# PIC32MK1024MCF064 device description
Architecture: MIPS; Family: PIC32MK; Series: PIC32MK
Registers are 32-bit, read-write, no defined reset value unless marked. A register's access mark holds for its fields unless they carry their own. Offsets are from the block's base; [hi:lo] are bit positions; {n}, {i} and the like mark numbered series; 'fields as' and 'values as' point back to an identical list.

## GPIO
Instances: GPIO 0x1f860000 in periph_pb4_std
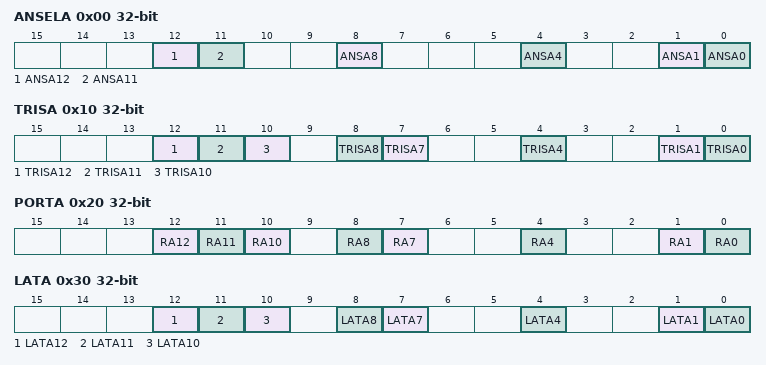
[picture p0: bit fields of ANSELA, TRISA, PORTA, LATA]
0x00 ANSELA
  [12] ANSA12, [11] ANSA11, [8] ANSA8, [4] ANSA4, [1] ANSA1, [0] ANSA0
0x10 TRISA
  [12] TRISA12, [11] TRISA11, [10] TRISA10, [8] TRISA8, [7] TRISA7, [4] TRISA4, [1] TRISA1, [0] TRISA0
0x20 PORTA
  [12] RA12, [11] RA11, [10] RA10, [8] RA8, [7] RA7, [4] RA4, [1] RA1, [0] RA0
0x30 LATA
  [12] LATA12, [11] LATA11, [10] LATA10, [8] LATA8, [7] LATA7, [4] LATA4, [1] LATA1, [0] LATA0
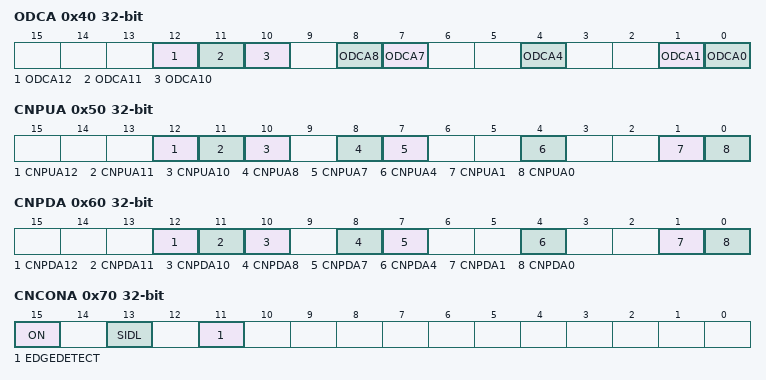
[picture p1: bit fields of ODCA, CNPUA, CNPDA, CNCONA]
0x40 ODCA
  [12] ODCA12, [11] ODCA11, [10] ODCA10, [8] ODCA8, [7] ODCA7, [4] ODCA4, [1] ODCA1, [0] ODCA0
0x50 CNPUA
  [12] CNPUA12, [11] CNPUA11, [10] CNPUA10, [8] CNPUA8, [7] CNPUA7, [4] CNPUA4, [1] CNPUA1, [0] CNPUA0
0x60 CNPDA
  [12] CNPDA12, [11] CNPDA11, [10] CNPDA10, [8] CNPDA8, [7] CNPDA7, [4] CNPDA4, [1] CNPDA1, [0] CNPDA0
0x70 CNCONA — Change Notice control for PORTx Register
  [15] ON — Change Notice Control ON bit
    1=CN is enabled; 0=CN is disabled
  [13] SIDL
  [11] EDGEDETECT — Change Notification Style bit
    1=Edge Style. Detect edge transitions (CNFx used for CN Event).; 0=Mismatch Style. Detect change from last PORTx read (CNSTATx used for CN Event).
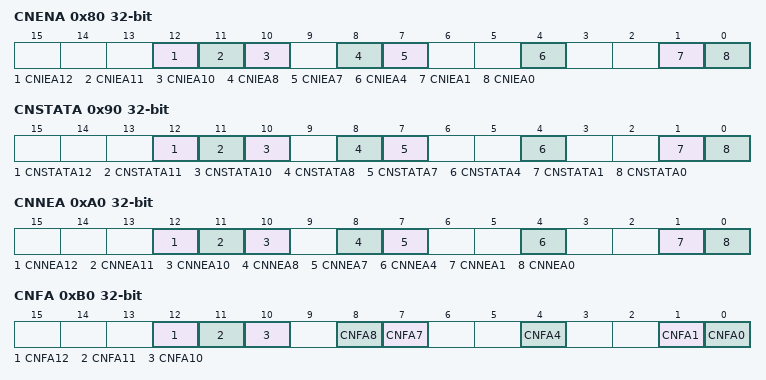
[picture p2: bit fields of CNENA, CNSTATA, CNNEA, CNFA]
0x80 CNENA
  [12] CNIEA12, [11] CNIEA11, [10] CNIEA10, [8] CNIEA8, [7] CNIEA7, [4] CNIEA4, [1] CNIEA1, [0] CNIEA0
0x90 CNSTATA
  [12] CNSTATA12, [11] CNSTATA11, [10] CNSTATA10, [8] CNSTATA8, [7] CNSTATA7, [4] CNSTATA4, [1] CNSTATA1, [0] CNSTATA0
0xA0 CNNEA
  [12] CNNEA12, [11] CNNEA11, [10] CNNEA10, [8] CNNEA8, [7] CNNEA7, [4] CNNEA4, [1] CNNEA1, [0] CNNEA0
0xB0 CNFA
  [12] CNFA12, [11] CNFA11, [10] CNFA10, [8] CNFA8, [7] CNFA7, [4] CNFA4, [1] CNFA1, [0] CNFA0
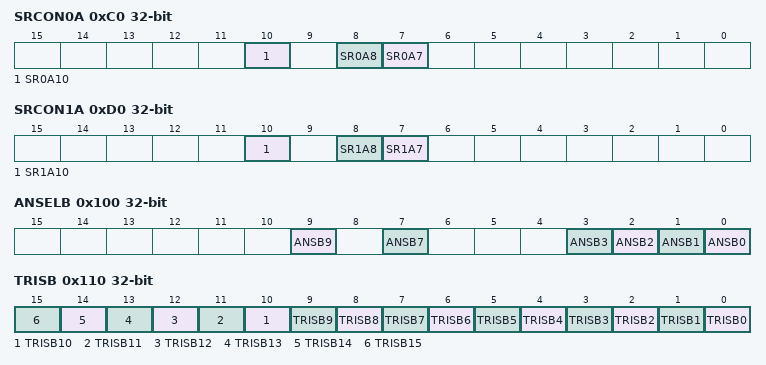
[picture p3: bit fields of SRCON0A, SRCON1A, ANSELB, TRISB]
0xC0 SRCON0A
  [10] SR0A10, [8] SR0A8, [7] SR0A7
0xD0 SRCON1A
  [10] SR1A10, [8] SR1A8, [7] SR1A7
0x100 ANSELB
  [9] ANSB9, [7] ANSB7, [n] ANSB{n} (n=0..3)
0x110 TRISB
  [n] TRISB{n} (n=0..15)
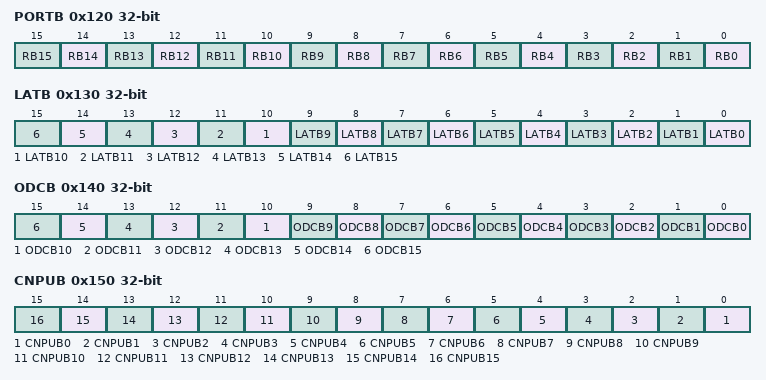
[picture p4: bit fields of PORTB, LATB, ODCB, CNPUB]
0x120 PORTB
  [n] RB{n} (n=0..15)
0x130 LATB
  [n] LATB{n} (n=0..15)
0x140 ODCB
  [n] ODCB{n} (n=0..15)
0x150 CNPUB
  [n] CNPUB{n} (n=0..15)
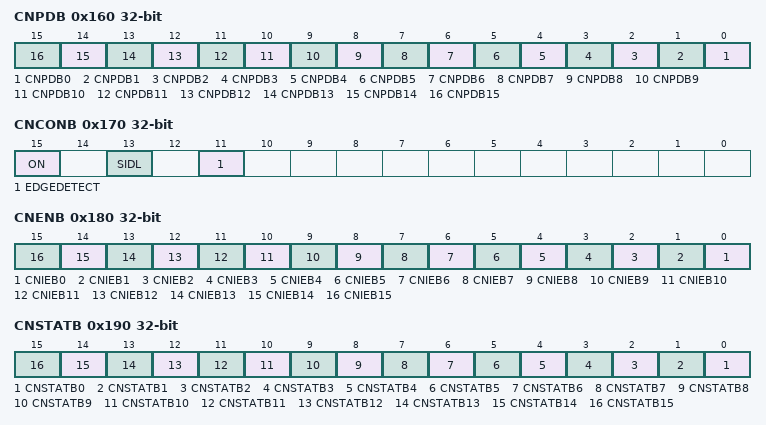
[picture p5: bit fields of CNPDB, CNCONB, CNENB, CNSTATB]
0x160 CNPDB
  [n] CNPDB{n} (n=0..15)
0x170 CNCONB — Change Notice control for PORTx Register
  fields as CNCONA
0x180 CNENB
  [n] CNIEB{n} (n=0..15)
0x190 CNSTATB
  [n] CNSTATB{n} (n=0..15)
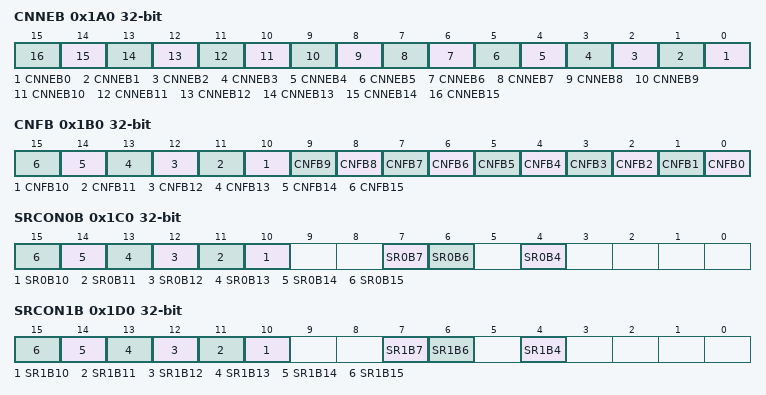
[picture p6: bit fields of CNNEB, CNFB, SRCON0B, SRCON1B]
0x1A0 CNNEB
  [n] CNNEB{n} (n=0..15)
0x1B0 CNFB
  [n] CNFB{n} (n=0..15)
0x1C0 SRCON0B
  [n] SR0B{n} (n=10..15), [7] SR0B7, [6] SR0B6, [4] SR0B4
0x1D0 SRCON1B
  [n] SR1B{n} (n=10..15), [7] SR1B7, [6] SR1B6, [4] SR1B4
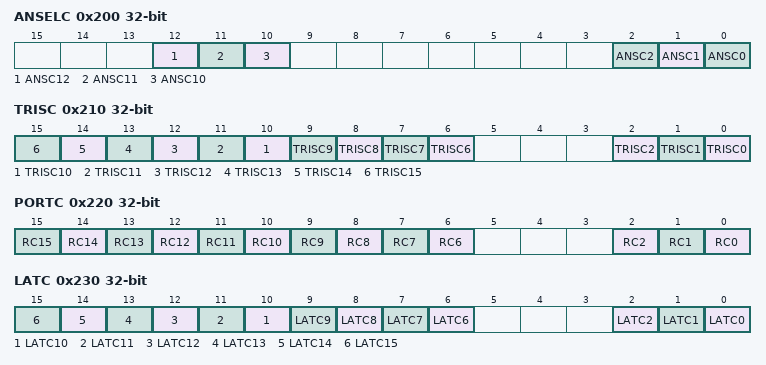
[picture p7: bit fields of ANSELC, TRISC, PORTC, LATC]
0x200 ANSELC
  [12] ANSC12, [11] ANSC11, [10] ANSC10, [2] ANSC2, [1] ANSC1, [0] ANSC0
0x210 TRISC
  [n] TRISC{n} (n=6..15), [2] TRISC2, [1] TRISC1, [0] TRISC0
0x220 PORTC
  [n] RC{n} (n=6..15), [2] RC2, [1] RC1, [0] RC0
0x230 LATC
  [n] LATC{n} (n=6..15), [2] LATC2, [1] LATC1, [0] LATC0
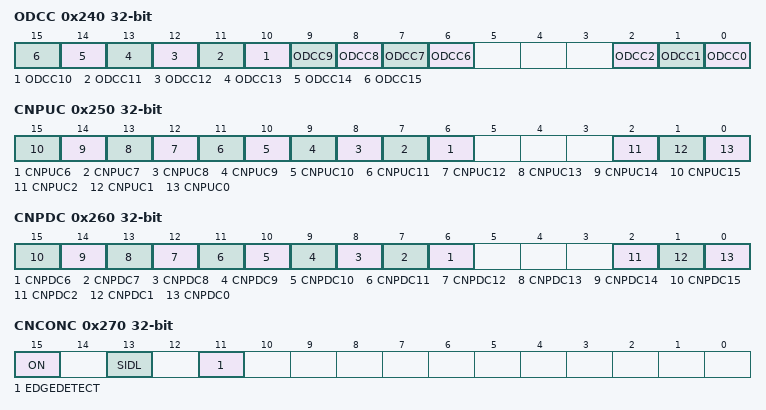
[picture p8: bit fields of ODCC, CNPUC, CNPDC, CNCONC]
0x240 ODCC
  [n] ODCC{n} (n=6..15), [2] ODCC2, [1] ODCC1, [0] ODCC0
0x250 CNPUC
  [n] CNPUC{n} (n=6..15), [2] CNPUC2, [1] CNPUC1, [0] CNPUC0
0x260 CNPDC
  [n] CNPDC{n} (n=6..15), [2] CNPDC2, [1] CNPDC1, [0] CNPDC0
0x270 CNCONC — Change Notice control for PORTx Register
  fields as CNCONA
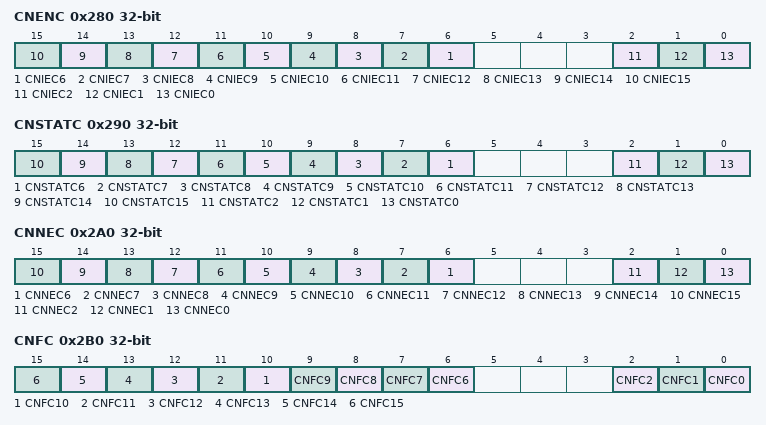
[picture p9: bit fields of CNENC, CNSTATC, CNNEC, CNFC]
0x280 CNENC
  [n] CNIEC{n} (n=6..15), [2] CNIEC2, [1] CNIEC1, [0] CNIEC0
0x290 CNSTATC
  [n] CNSTATC{n} (n=6..15), [2] CNSTATC2, [1] CNSTATC1, [0] CNSTATC0
0x2A0 CNNEC
  [n] CNNEC{n} (n=6..15), [2] CNNEC2, [1] CNNEC1, [0] CNNEC0
0x2B0 CNFC
  [n] CNFC{n} (n=6..15), [2] CNFC2, [1] CNFC1, [0] CNFC0
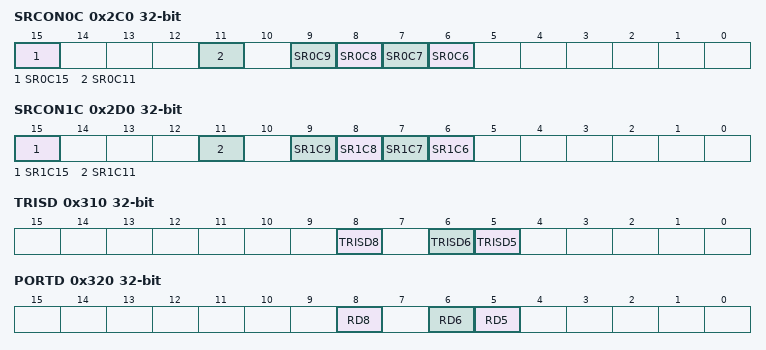
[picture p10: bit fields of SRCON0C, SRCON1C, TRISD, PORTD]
0x2C0 SRCON0C
  [15] SR0C15, [11] SR0C11, [n] SR0C{n} (n=6..9)
0x2D0 SRCON1C
  [15] SR1C15, [11] SR1C11, [n] SR1C{n} (n=6..9)
0x310 TRISD
  [8] TRISD8, [6] TRISD6, [5] TRISD5
0x320 PORTD
  [8] RD8, [6] RD6, [5] RD5
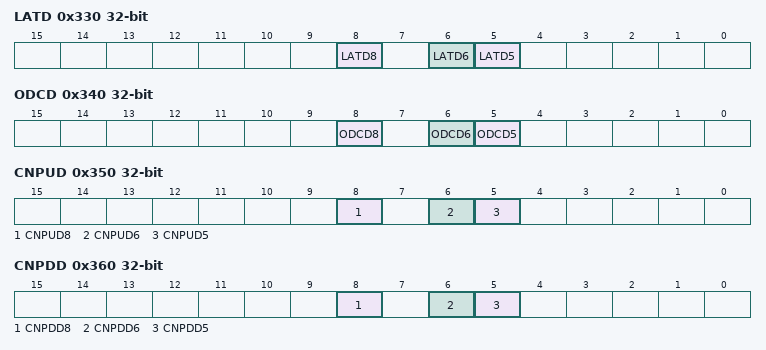
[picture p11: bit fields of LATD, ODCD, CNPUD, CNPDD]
0x330 LATD
  [8] LATD8, [6] LATD6, [5] LATD5
0x340 ODCD
  [8] ODCD8, [6] ODCD6, [5] ODCD5
0x350 CNPUD
  [8] CNPUD8, [6] CNPUD6, [5] CNPUD5
0x360 CNPDD
  [8] CNPDD8, [6] CNPDD6, [5] CNPDD5
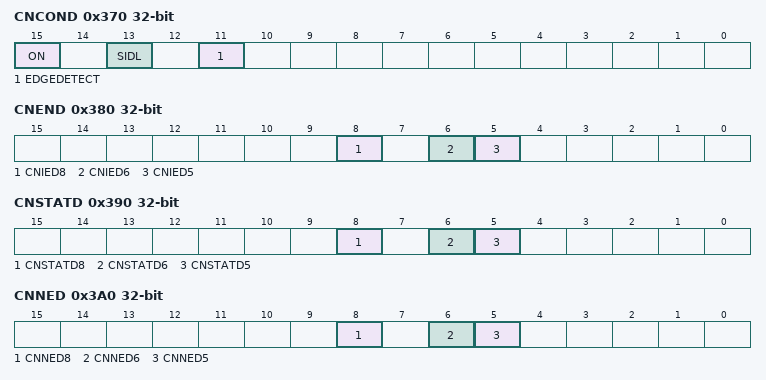
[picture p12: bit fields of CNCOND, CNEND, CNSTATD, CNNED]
0x370 CNCOND — Change Notice control for PORTx Register
  fields as CNCONA
0x380 CNEND
  [8] CNIED8, [6] CNIED6, [5] CNIED5
0x390 CNSTATD
  [8] CNSTATD8, [6] CNSTATD6, [5] CNSTATD5
0x3A0 CNNED
  [8] CNNED8, [6] CNNED6, [5] CNNED5
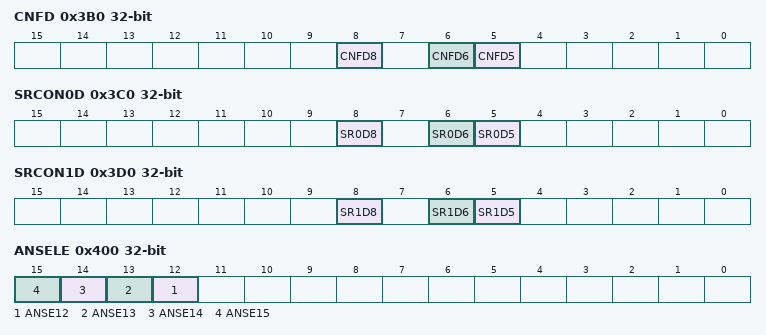
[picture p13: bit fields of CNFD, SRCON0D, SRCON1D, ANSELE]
0x3B0 CNFD
  [8] CNFD8, [6] CNFD6, [5] CNFD5
0x3C0 SRCON0D
  [8] SR0D8, [6] SR0D6, [5] SR0D5
0x3D0 SRCON1D
  [8] SR1D8, [6] SR1D6, [5] SR1D5
0x400 ANSELE
  [n] ANSE{n} (n=12..15)
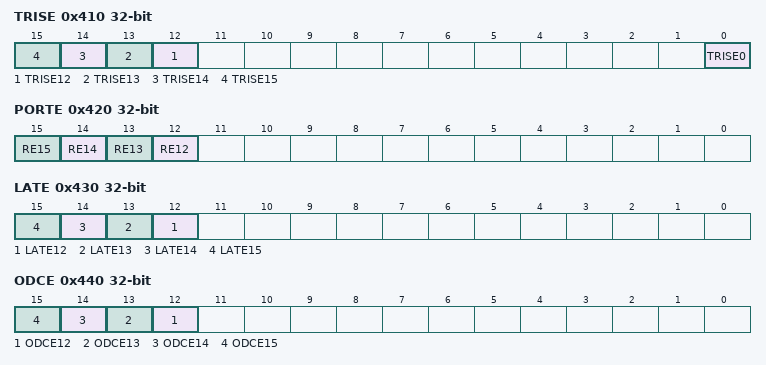
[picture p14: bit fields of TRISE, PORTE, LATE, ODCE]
0x410 TRISE
  [n] TRISE{n} (n=12..15), [0] TRISE0
0x420 PORTE
  [n] RE{n} (n=12..15)
0x430 LATE
  [n] LATE{n} (n=12..15)
0x440 ODCE
  [n] ODCE{n} (n=12..15)
0x450 CNPUE
  [n] CNPUE{n} (n=12..15)
0x460 CNPDE
  [n] CNPDE{n} (n=12..15)
0x470 CNCONE — Change Notice control for PORTx Register
  fields as CNCONA
0x480 CNENE
  [n] CNIEE{n} (n=12..15)
0x490 CNSTATE
  [n] CNSTATE{n} (n=12..15)
0x4A0 CNNEE
  [n] CNNEE{n} (n=12..15)
0x4B0 CNFE
  [n] CNFE{n} (n=12..15)
0x4C0 SRCON0E
  [n] SR0E{n} (n=12..15)
0x4D0 SRCON1E
  [n] SR1E{n} (n=12..15)
0x510 TRISF
  [1] TRISF1, [0] TRISF0
0x520 PORTF
  [1] RF1, [0] RF0
0x530 LATF
  [1] LATF1, [0] LATF0
0x540 ODCF
  [1] ODCF1, [0] ODCF0
0x550 CNPUF
  [1] CNPUF1, [0] CNPUF0
0x560 CNPDF
  [1] CNPDF1, [0] CNPDF0
0x570 CNCONF — Change Notice control for PORTx Register
  fields as CNCONA
0x580 CNENF
  [1] CNIEF1, [0] CNIEF0
0x590 CNSTATF
  [1] CNSTATF1, [0] CNSTATF0
0x5A0 CNNEF
  [1] CNNEF1, [0] CNNEF0
0x5B0 CNFF
  [1] CNFF1, [0] CNFF0
0x5C0 SRCON0F
  [1] SR0F1, [0] SR0F0
0x5D0 SRCON1F
  [1] SR1F1, [0] SR1F0
0x600 ANSELG
  [n] ANSG{n} (n=6..9)
0x610 TRISG
  [n] TRISG{n} (n=6..9)
0x620 PORTG
  [n] RG{n} (n=6..9)
0x630 LATG
  [n] LATG{n} (n=6..9)
0x640 ODCG
  [n] ODCG{n} (n=6..9)
0x650 CNPUG
  [n] CNPUG{n} (n=6..9)
0x660 CNPDG
  [n] CNPDG{n} (n=6..9)
0x670 CNCONG — Change Notice control for PORTx Register
  fields as CNCONA
0x680 CNENG
  [n] CNIEG{n} (n=6..9)
0x690 CNSTATG
  [n] CNSTATG{n} (n=6..9)
0x6A0 CNNEG
  [n] CNNEG{n} (n=6..9)
0x6B0 CNFG
  [n] CNFG{n} (n=6..9)

## Notices in the file
Copyright (c) 2017 Microchip Technology Inc.
SPDX-License-Identifier: Apache-2.0
Licensed under the Apache License, Version 2.0 (the "License");
you may not use this file except in compliance with the License.
You may obtain a copy of the License at
http://www.apache.org/licenses/LICENSE-2.0
Unless required by applicable law or agreed to in writing, software
distributed under the License is distributed on an "AS IS" BASIS,
WITHOUT WARRANTIES OR CONDITIONS OF ANY KIND, either express or implied.
See the License for the specific language governing permissions and
limitations under the License.
